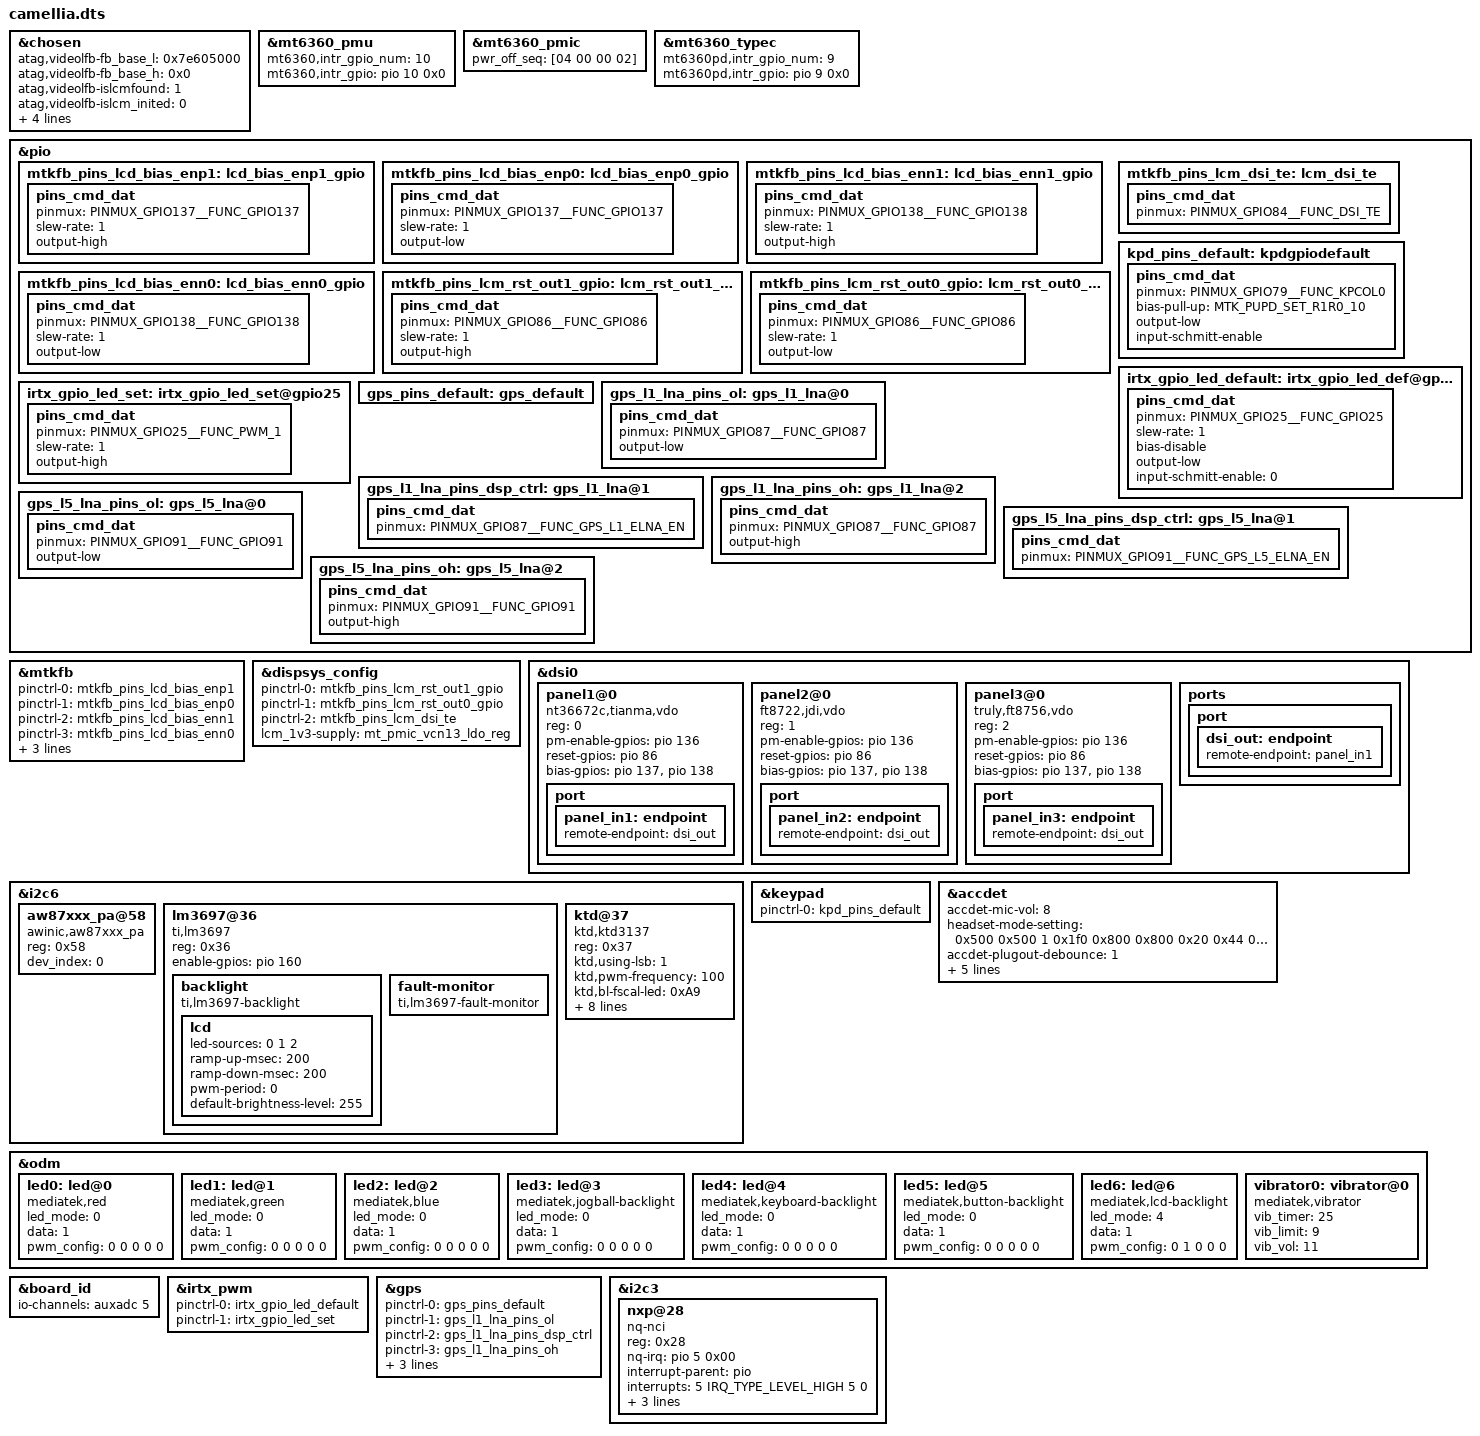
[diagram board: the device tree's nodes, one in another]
// SPDX-License-Identifier: GPL-2.0
/*
 * Copyright (c) 2019 MediaTek Inc.
 *
 */
/dts-v1/;
/plugin/;
#include <dt-bindings/interrupt-controller/irq.h>
#include <dt-bindings/interrupt-controller/arm-gic.h>
#ifndef CONFIG_FPGA_EARLY_PORTING
#include <dt-bindings/pinctrl/mt6833-pinfunc.h>
#endif

#include "mediatek/light-sia8152.dtsi"

/* chosen */
&chosen {
	atag,videolfb-fb_base_l = <0x7e605000>;
	atag,videolfb-fb_base_h = <0x0>;
	atag,videolfb-islcmfound = <1>;
	atag,videolfb-islcm_inited = <0>;
	atag,videolfb-fps= <6000>;
	atag,videolfb-vramSize= <0x1be0000>;
	atag,videolfb-lcmname=
		"dsi_panel_l19_36_02_0a_dsc_vdo_lcm_drv";
};

&mt6360_pmu {
	mt6360,intr_gpio_num = <10>; /* direct defined GPIO num */
	mt6360,intr_gpio = <&pio 10 0x0>;
};

&mt6360_pmic {
	pwr_off_seq = [04 00 00 02];
};
/*L19 HQ-157291 USB and Charge bring up by miaozhichao at 2021/10/1 start*/
&mt6360_typec {
	mt6360pd,intr_gpio_num = <9>; /* direct defined GPIO num */
	mt6360pd,intr_gpio = <&pio 9 0x0>;
};
/*L19 HQ-157291 USB and Charge bring up by miaozhichao at 2021/10/1 end*/
#ifndef CONFIG_FPGA_EARLY_PORTING
&pio {
	mtkfb_pins_lcd_bias_enp1: lcd_bias_enp1_gpio {
		pins_cmd_dat {
			pinmux = <PINMUX_GPIO137__FUNC_GPIO137>;
			slew-rate = <1>;
			output-high;
		};
	};

	mtkfb_pins_lcd_bias_enp0: lcd_bias_enp0_gpio {
		pins_cmd_dat {
			pinmux = <PINMUX_GPIO137__FUNC_GPIO137>;
			slew-rate = <1>;
			output-low;
		};
	};

	mtkfb_pins_lcd_bias_enn1: lcd_bias_enn1_gpio {
		pins_cmd_dat {
			pinmux = <PINMUX_GPIO138__FUNC_GPIO138>;
			slew-rate = <1>;
			output-high;
		};
	};

	mtkfb_pins_lcd_bias_enn0: lcd_bias_enn0_gpio {
		pins_cmd_dat {
			pinmux = <PINMUX_GPIO138__FUNC_GPIO138>;
			slew-rate = <1>;
			output-low;
		};
	};

	mtkfb_pins_lcm_rst_out1_gpio: lcm_rst_out1_gpio {
		pins_cmd_dat {
			pinmux = <PINMUX_GPIO86__FUNC_GPIO86>;
			slew-rate = <1>;
			output-high;
		};
	};

	mtkfb_pins_lcm_rst_out0_gpio: lcm_rst_out0_gpio {
		pins_cmd_dat {
			pinmux = <PINMUX_GPIO86__FUNC_GPIO86>;
			slew-rate = <1>;
			output-low;
		};
	};
	mtkfb_pins_lcm_dsi_te: lcm_dsi_te {
		pins_cmd_dat {
			pinmux = <PINMUX_GPIO84__FUNC_DSI_TE>;
		};
	};
};

&mtkfb {
	pinctrl-names = "lcd_bias_enp1_gpio", "lcd_bias_enp0_gpio",
		"lcd_bias_enn1_gpio", "lcd_bias_enn0_gpio",
		"lcm_rst_out1_gpio", "lcm_rst_out0_gpio",
		"mode_te_te";
	pinctrl-0 = <&mtkfb_pins_lcd_bias_enp1>;
	pinctrl-1 = <&mtkfb_pins_lcd_bias_enp0>;
	pinctrl-2 = <&mtkfb_pins_lcd_bias_enn1>;
	pinctrl-3 = <&mtkfb_pins_lcd_bias_enn0>;
	pinctrl-4 = <&mtkfb_pins_lcm_rst_out1_gpio>;
	pinctrl-5 = <&mtkfb_pins_lcm_rst_out0_gpio>;
	pinctrl-6 = <&mtkfb_pins_lcm_dsi_te>;
	status = "okay";
};
&dispsys_config {
	pinctrl-names =
		"lcm_rst_out1_gpio", "lcm_rst_out0_gpio",
		"mode_te_te";
	pinctrl-0 = <&mtkfb_pins_lcm_rst_out1_gpio>;
	pinctrl-1 = <&mtkfb_pins_lcm_rst_out0_gpio>;
	pinctrl-2 = <&mtkfb_pins_lcm_dsi_te>;
	lcm_1v3-supply = <&mt_pmic_vcn13_ldo_reg>;
	status = "okay";
};

&dsi0 {
	status = "okay";
	#address-cells = <1>;
	#size-cells = <0>;
	panel1@0 {
		compatible = "nt36672c,tianma,vdo";
		reg = <0>;
		pm-enable-gpios = <&pio 136 0>;
		reset-gpios = <&pio 86 0>;
		bias-gpios = <&pio 137 0>,
			<&pio 138 0>;
		pinctrl-names = "default";
		port {
			panel_in1: endpoint {
				remote-endpoint = <&dsi_out>;
			};
		};
	};
	panel2@0 {
		compatible = "ft8722,jdi,vdo";
		reg = <1>;
		pm-enable-gpios = <&pio 136 0>;
		reset-gpios = <&pio 86 0>;
		bias-gpios = <&pio 137 0>,
			<&pio 138 0>;
		pinctrl-names = "default";
		port {
			panel_in2: endpoint {
				remote-endpoint = <&dsi_out>;
			};
		};
	};
	panel3@0 {
		compatible = "truly,ft8756,vdo";
		reg = <2>;
		pm-enable-gpios = <&pio 136 0>;
		reset-gpios = <&pio 86 0>;
		bias-gpios = <&pio 137 0>,
			<&pio 138 0>;
		pinctrl-names = "default";
		port {
			panel_in3: endpoint {
				remote-endpoint = <&dsi_out>;
			};
		};
	};
	ports {
		port {
			dsi_out: endpoint {
				remote-endpoint = <&panel_in1>;
			};
		};
	};
};
#endif


&i2c6 {
                aw87xxx_pa@58 {
                                compatible = "awinic,aw87xxx_pa";
                                reg = <0x58>;
                                dev_index = < 0 >;
                                status = "okay";
                };
};


&keypad {
	pinctrl-names = "default";
	pinctrl-0 = <&kpd_pins_default>;
};

&pio {
	kpd_pins_default: kpdgpiodefault {
		pins_cmd_dat {
			pinmux = <PINMUX_GPIO79__FUNC_KPCOL0>;
			bias-pull-up = <MTK_PUPD_SET_R1R0_10>;
			output-low;
			input-schmitt-enable;
		};
	};
};


/*#include "mediatek/cust_mt6833_touch_1080x2300.dtsi"*/
#include "mediatek/cust_mt6833_touch_1080x2400.dtsi"
/* accdet start */
&accdet {
	/* accdet micbias voltage: 0x09:2.85v 0x08:2.8v 0x07,
	 * 2.7v;0x05,2.5v;0x02,1.9v
	 */
	accdet-mic-vol = <8>;
	/* accdet pwm_width, pwm_thresh, fall_delay, rise_delay
	 * debounce0, debounce1, debounce3, debounce4
	 * eint pwm_width, eint pwm_thresh
	 * eint deb(debounce0, debounce1, debounce2, debounce3), inv_debounce
	 */
	headset-mode-setting = <0x500 0x500 1 0x1f0
				0x800 0x800 0x20 0x44
				0x4 0x1
				0x5 0x3 0x3 0x5 0xe>;
	accdet-plugout-debounce = <1>;
	/*1:ACC mode, 2:low cost without in bias, 6:low cost with in bias*/
	accdet-mic-mode = <2>;
	/*0--MD_MAX--UP_MAX--DW_MAX*/
	headset-three-key-threshold = <0 80 220 400>;
	headset-three-key-threshold-CDD = <0 121 192 600>;
	/*0--MD_MAX--VOICE_MAX--UP_MAX--DW_MAX*/
	headset-four-key-threshold = <0 58 121 192 400>;

	/* select VTH to 2v and 500k, use internal resitance */
	eint_use_ext_res = <0>;
	status = "okay";
};
/* accdet end */

&odm {
	led0:led@0 {
		compatible = "mediatek,red";
		led_mode = <0>;
		data = <1>;
		pwm_config = <0 0 0 0 0>;
	};
	led1:led@1 {
		compatible = "mediatek,green";
		led_mode = <0>;
		data = <1>;
		pwm_config = <0 0 0 0 0>;
	};
	led2:led@2 {
		compatible = "mediatek,blue";
		led_mode = <0>;
		data = <1>;
		pwm_config = <0 0 0 0 0>;
	};
	led3:led@3 {
		compatible = "mediatek,jogball-backlight";
		led_mode = <0>;
		data = <1>;
		pwm_config = <0 0 0 0 0>;
	};
	led4:led@4 {
		compatible = "mediatek,keyboard-backlight";
		led_mode = <0>;
		data = <1>;
		pwm_config = <0 0 0 0 0>;
	};
	led5:led@5 {
		compatible = "mediatek,button-backlight";
		led_mode = <0>;
		data = <1>;
		pwm_config = <0 0 0 0 0>;
	};
	led6:led@6 {
		compatible = "mediatek,lcd-backlight";
		led_mode = <4>;
		data = <1>;
		pwm_config = <0 1 0 0 0>;
	};
/* Huaqin modify for HQ-162861 by wangzhaoguo at 2021/10/28 start */
	vibrator0:vibrator@0 {
		compatible = "mediatek,vibrator";
		vib_timer = <25>;
		vib_limit = <9>;
		vib_vol= <11>;
	};
/* Huaqin modify for HQ-162861 by wangzhaoguo at 2021/10/28 end */
};

/* Huaqin modify for HQ-158772  by wangzhaoguo at 2021/10/18 start */
&board_id {
	io-channels = <&auxadc 5>;
	io-channel-names = "board_id-channel";
	status = "okay";
};
/* Huaqin modify for HQ-158772  by wangzhaoguo at 2021/10/18 end */
/* Huaqin modify for HQ-161121 by yangjinhao at 2021/10/19 start */
&pio {
	/* IRTX GPIO Settings -Start */
	/* default: GPIO0, output, high */
	irtx_gpio_led_default:irtx_gpio_led_def@gpio25 {
		pins_cmd_dat {
			pinmux = <PINMUX_GPIO25__FUNC_GPIO25>;
			slew-rate = <1>;
			bias-disable;
			output-low;
			input-schmitt-enable = <0>;
		};
	};

	irtx_gpio_led_set:irtx_gpio_led_set@gpio25 {
		pins_cmd_dat {
			pinmux = <PINMUX_GPIO25__FUNC_PWM_1>;
			slew-rate = <1>;
			output-high;
		};
	};
}; /* IRTX GPIO Settings -End */

&irtx_pwm {
	pinctrl-names = "irtx_gpio_led_default", "irtx_gpio_led_set";
	pinctrl-0 = <&irtx_gpio_led_default>;
	pinctrl-1 = <&irtx_gpio_led_set>;
	status = "okay";
};
/* Huaqin modify for HQ-161121 by yangjinhao at 2021/10/19 end */

/* GPS GPIO standardization start */
&pio {
	gps_pins_default: gps_default {
	};

	gps_l1_lna_pins_ol: gps_l1_lna@0 {
		pins_cmd_dat {
			pinmux = <PINMUX_GPIO87__FUNC_GPIO87>;
			output-low;
		};
	};
	gps_l1_lna_pins_dsp_ctrl: gps_l1_lna@1 {
		pins_cmd_dat {
			pinmux = <PINMUX_GPIO87__FUNC_GPS_L1_ELNA_EN>;
		};
	};
	gps_l1_lna_pins_oh: gps_l1_lna@2 {
		pins_cmd_dat {
			pinmux = <PINMUX_GPIO87__FUNC_GPIO87>;
			output-high;
		};
	};

	gps_l5_lna_pins_ol: gps_l5_lna@0 {
		pins_cmd_dat {
			pinmux = <PINMUX_GPIO91__FUNC_GPIO91>;
			output-low;
		};
	};
	gps_l5_lna_pins_dsp_ctrl: gps_l5_lna@1 {
		pins_cmd_dat {
			pinmux = <PINMUX_GPIO91__FUNC_GPS_L5_ELNA_EN>;
		};
	};
	gps_l5_lna_pins_oh: gps_l5_lna@2 {
		pins_cmd_dat {
			pinmux = <PINMUX_GPIO91__FUNC_GPIO91>;
			output-high;
		};
	};
};

&gps {
	pinctrl-names = "default",
		"gps_l1_lna_disable",
		"gps_l1_lna_dsp_ctrl",
		"gps_l1_lna_enable",
		"gps_l5_lna_disable",
		"gps_l5_lna_dsp_ctrl",
		"gps_l5_lna_enable";
	pinctrl-0 = <&gps_pins_default>;
	pinctrl-1 = <&gps_l1_lna_pins_ol>;
	pinctrl-2 = <&gps_l1_lna_pins_dsp_ctrl>;
	pinctrl-3 = <&gps_l1_lna_pins_oh>;
	pinctrl-4 = <&gps_l5_lna_pins_ol>;
	pinctrl-5 = <&gps_l5_lna_pins_dsp_ctrl>;
	pinctrl-6 = <&gps_l5_lna_pins_oh>;
	status = "okay";
};

/* L19 code for HQ-159057 by lukuan at 2021.10.27 start */
&i2c3 {
    nxp@28 {
        compatible = "nq-nci";
        reg = <0x28>;
        nq-irq = <&pio 5 0x00>;
        interrupt-parent = <&pio>;
        interrupts = <5 IRQ_TYPE_LEVEL_HIGH 5 0>;
        nq-ven = <&pio 140 0x0>;
        nq-firm = <&pio 30 0x0>;
        nq-clkreq = <&pio 81 0x0>;
        interrupt-names = "irq_nfc";
        status = "okay";
    };
};
/* L19 code for HQ-159057 by lukuan at 2021.10.27 end */
/* Huaqin add for HQ-158035 by caogaojie at 2021/10/29 start */
&i2c6 {
	lm3697@36 {
		compatible = "ti,lm3697";
		reg = <0x36>;
		status = "okay";
		enable-gpios = <&pio 160 0>;
		backlight {
			compatible = "ti,lm3697-backlight";
			lcd {
				led-sources = <0 1 2>;
				ramp-up-msec = <200>;
				ramp-down-msec = <200>;
				pwm-period = <0>;
				default-brightness-level = <255>;
			};
		};
		fault-monitor {
			compatible = "ti,lm3697-fault-monitor";
		};
	};
/* Huaqin add for HQ-157668 by caogaojie at 2021/11/7 start */
	ktd@37 {
		compatible = "ktd,ktd3137";
		reg = <0x37>;
		status = "okay";
		/*ktd,pwm-mode; */
		ktd,using-lsb = <1>;
		ktd,pwm-frequency = <100>;
		ktd,bl-fscal-led = <0xA9>;/*default 21.8mA*/
		ktd,turn-on-ramp = <0>;
		ktd,turn-off-ramp = <0>;
		ktd,pwm-trans-dim = <0>;
		ktd,i2c-trans-dim = <0>;
		ktd,bl-channel = <2>;
		ktd,ovp-level = <32>; /*default 32v*/
		ktd,switching-frequency = <1000>; /*default 1000kHz*/
		ktd,inductor-current = <2600>; //default 2600mA
		};
/* Huaqin add for HQ-157668 by caogaojie at 2021/11/7 end */
};
/* Huaqin add for HQ-158035 by caogaojie at 2021/10/29 end */
/* GPS GPIO standardization end */
#include "mediatek/cust_light_camera.dtsi"
#include <light/cust.dtsi>
#include "mediatek/cust_light_fingerprint.dtsi"

/*End of this file, DO NOT ADD ANYTHING HERE*/
